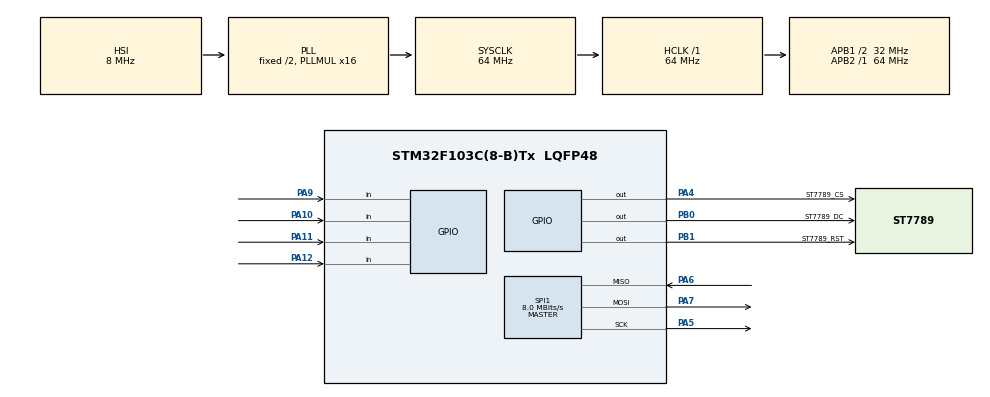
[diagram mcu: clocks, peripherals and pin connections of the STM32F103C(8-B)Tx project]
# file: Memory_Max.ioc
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Mcu.Family=STM32F1
Mcu.Name=STM32F103C(8-B)Tx
Mcu.Package=LQFP48
NVIC.PriorityGroup=NVIC_PRIORITYGROUP_4
PA10.GPIO_PuPd=GPIO_PULLUP
PA10.Signal=GPIO_Input
PA11.GPIO_PuPd=GPIO_PULLUP
PA11.Signal=GPIO_Input
PA12.GPIO_PuPd=GPIO_PULLUP
PA12.Signal=GPIO_Input
PA13.Mode=Serial_Wire
PA13.Signal=SYS_JTMS-SWDIO
PA14.Mode=Serial_Wire
PA14.Signal=SYS_JTCK-SWCLK
PA4.GPIO_Label=ST7789_CS 
PA4.Signal=GPIO_Output
PA5.Mode=Full_Duplex_Master
PA5.Signal=SPI1_SCK
PA6.Mode=Full_Duplex_Master
PA6.Signal=SPI1_MISO
PA7.Mode=Full_Duplex_Master
PA7.Signal=SPI1_MOSI
PA9.GPIO_PuPd=GPIO_PULLUP
PA9.Signal=GPIO_Input
PB0.GPIO_Label=ST7789_DC 
PB0.Signal=GPIO_Output
PB1.GPIO_Label=ST7789_RST 
PB1.Signal=GPIO_Output
ProjectManager.HeapSize=0x200
ProjectManager.StackSize=0x400
ProjectManager.TargetToolchain=STM32CubeIDE
RCC.AHBFreq_Value=64000000
RCC.APB1CLKDivider=RCC_HCLK_DIV2
RCC.APB1Freq_Value=32000000
RCC.APB1TimFreq_Value=64000000
RCC.APB2Freq_Value=64000000
RCC.APB2TimFreq_Value=64000000
RCC.HCLKFreq_Value=64000000
RCC.PLLMUL=RCC_PLL_MUL16
RCC.SYSCLKFreq_VALUE=64000000
RCC.SYSCLKSource=RCC_SYSCLKSOURCE_PLLCLK
RCC.USBFreq_Value=64000000
SPI1.BaudRatePrescaler=SPI_BAUDRATEPRESCALER_8
SPI1.CLKPolarity=SPI_POLARITY_HIGH
SPI1.CalculateBaudRate=8.0 MBits/s
SPI1.Direction=SPI_DIRECTION_2LINES
SPI1.Mode=SPI_MODE_MASTER
SPI1.VirtualType=VM_MASTER
board=custom

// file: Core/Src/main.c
/* USER CODE BEGIN Header */
/**
  ******************************************************************************
  * @file           : main.c
  * @brief          : Main program body
  ******************************************************************************
  * @attention
  *
  * <h2><center>&copy; Copyright (c) 2025 STMicroelectronics.
  * All rights reserved.</center></h2>
  *
  * This software component is licensed by ST under BSD 3-Clause license,
  * the "License"; You may not use this file except in compliance with the
  * License. You may obtain a copy of the License at:
  *                        opensource.org/licenses/BSD-3-Clause
  *
  ******************************************************************************
  */
/* USER CODE END Header */
#include "main.h"

/* USER CODE BEGIN Includes */
#include "st7789\st7789.h"
#include "stdbool.h"
#include "jogo.h"
#include "stdlib.h"
#include "stdio.h"
/* USER CODE END Includes */

SPI_HandleTypeDef hspi1;

/* USER CODE BEGIN PV */
static const uint64_t hearts[50] = {0x00,0x00,0x1E0003E000,0x60800C1800,0x9E6013E400,0x37F902FFA00,0x7FFE85FFD00,0xFFFFCBFFE80,0xBFFF57FFF40,0x17FFFBFFFFE0,0x3FFFFEFFFFA0,0x2FFFFDFFFFD0,0x5FFFFFFFFFF0,0x5FFFFFFFFFE8,0xBFFFFFFFFFE8,0xBFFFFFFFFFF4,0xBFFFFFFFFFF4,0xBFFFFFFFFFF4,0x17FFFFFFFFFF4,0x17FFFFFFFFFF4,0x17FFFFFFFFFF4,0xBFFFFFFFFFF4,0xBFFFFFFFFFF4,0xBFFFFFFFFFF4,0xBFFFFFFFFFE8,0x7FFFFFFFFFE8,0x5FFFFFFFFFE8,0x5FFFFFFFFFD0,0x2FFFFFFFFFD0,0x3FFFFFFFFFA0,0x17FFFFFFFFE0,0x1FFFFFFFFF40,0xBFFFFFFFFC0,0x5FFFFFFFE80,0x7FFFFFFFD00,0x2FFFFFFFA00,0x17FFFFFFE00,0xBFFFFFF400,0x5FFFFFE800,0x2FFFFFD000,0x17FFFFA000,0xBFFFE4000,0x5FFFD8000,0x27FFA0000,0x1BFE40000,0x4FD80000,0x37200000,0x8C00000,0x7000000,0x00};
static const uint64_t spades[50] = {0x13900000,0x6FEC0000,0x9FF20000,0x37FFD0000,0x4FFFE8000,0xBFFFF6000,0x17FFFFB000,0x2FFFFFF800,0x5FFFFFFC00,0xBFFFFFFE00,0x17FFFFFFB00,0x2FFFFFFFD00,0x7FFFFFFFE80,0x5FFFFFFFF40,0xBFFFFFFFFC0,0x1FFFFFFFFFA0,0x17FFFFFFFFF0,0x2FFFFFFFFFD0,0x2FFFFFFFFFE8,0x5FFFFFFFFFE8,0x5FFFFFFFFFF8,0xBFFFFFFFFFF4,0xBFFFFFFFFFF4,0xBFFFFFFFFFF4,0xBFFFFFFFFFFA,0xBFFFFFFFFFFA,0x17FFFFFFFFFFA,0x17FFFFFFFFFFA,0x17FFFFFFFFFFA,0x17FFFFFFFFFFA,0x7FFFFFFFFFFA,0xBFFFFFFFFFFA,0xBFFFFFFFFFF4,0xBFFFFFFFFFF4,0x7FFFFFFFFFF4,0x5FFFFFFFFFE8,0x3FFFFFFFFFF8,0x3FFFFFFFFFD0,0x17FFFFFFFFA0,0xBFFFFFFFF40,0x5FFEFDFFE80,0x27FDFE7FD00,0x18E7FF8E200,0x61DFEE1C00,0xE7FF5E000,0xFFF40000,0xBFF40000,0x17FFA0000,0x17FFF0000,0x7FFC0000};
static const uint64_t clubs[50] = {0xDFCC0000,0x13FF20000,0x2FFFD0000,0x5FFFF8000,0xFFFFE8000,0xBFFFF4000,0x17FFFFE000,0x17FFFFA000,0x2FFFFFA000,0x2FFFFFD000,0x2FFFFFD000,0x2FFFFFD000,0x2FFFFFD000,0x2FFFFFD000,0x7FFFFFF000,0x18FFFFFCC00,0x27FFFFFF300,0x5FFFFFFFC80,0xBFFFFFFFF40,0x17FFFFFFFFA0,0x2FFFFFFFFFF0,0x7FFFFFFFFFD0,0x5FFFFFFFFFE8,0xFFFFFFFFFFE8,0xBFFFFFFFFFF4,0xBFFFFFFFFFF4,0xBFFFFFFFFFF4,0x17FFFFFFFFFF4,0x17FFFFFFFFFF4,0x17FFFFFFFFFF4,0x3FFFFFFFFFF4,0xBFFFFFFFFFF4,0xBFFFFFFFFFF4,0xBFFFFFFFFFFC,0x5FFFFFFFFFE8,0x7FFFFFFFFFF8,0x2FFFFFFFFFD0,0x3FFFFFFFFFA0,0x1FFFFFFFFF40,0x9FFDFDFFE80,0x6FFBFE7FD00,0x1087FF84200,0xF7DFEF3C00,0x8BFF44000,0xBFFC0000,0xFFF40000,0x17FFA0000,0x3FFFE0000,0x2FFFC0000,0x00};
static const uint64_t diamonds[50] = {0xB400000,0x1FE00000,0x37F00000,0x2FD00000,0x5FE80000,0xBFF40000,0x17FFA0000,0x2FFFD0000,0x7FFFE8000,0xDFFFFC000,0xBFFFF6000,0x17FFFFA000,0x2FFFFFD000,0x5FFFFFE800,0xBFFFFFF400,0x1FFFFFFFA00,0x3FFFFFFFF00,0x2FFFFFFFD80,0x5FFFFFFFE80,0xBFFFFFFFF40,0x17FFFFFFFFA0,0x2FFFFFFFFFD0,0x5FFFFFFFFFE8,0xFFFFFFFFFFFC,0xBFFFFFFFFFF4,0xFFFFFFFFFFFC,0x5FFFFFFFFFE8,0x2FFFFFFFFFD0,0x17FFFFFFFFA0,0xBFFFFFFFF40,0x5FFFFFFFE80,0x2FFFFFFFD00,0x37FFFFFFF00,0x1FFFFFFFE00,0xBFFFFFF400,0x5FFFFFE800,0x2FFFFFD000,0x17FFFFA000,0xBFFFF4000,0xDFFFFC000,0x7FFFF8000,0x2FFFD0000,0x17FFA0000,0xBFF40000,0x5FE80000,0x2FD00000,0x17B00000,0x1FE00000,0xB400000,0x4800000};
static const uint16_t fundocarta[][(50*50/2)]  = {
  0x4eeb, 0x14f5, 0x51ec, 0x8eeb, 0x18f6, 0xd7f5, 0x39f6, 0xf8f5, 0x76ed, 0xb3f4, 0x96f5, 0x55ed, 0xf7f5, 0xf0eb, 0x59f6, 0x38f6, 0x8eeb, 0xd7f5, 0x59f6, 0x92ec, 0x14f5, 0x59f6, 0x55f5, 0x92f4, 0x18f6, 0x18f6, 0x92ec, 0x55f5, 0x59f6, 0x34f5, 0x92ec, 0x59f6, 0xd7f5, 0x8eeb, 0x38f6, 0x39f6, 0xd0eb, 0xf7f5, 0x55ed, 0x96f5, 0xb3f4, 0x76ed, 0x18f6, 0x39f6, 0xd7f5, 0x18f6, 0x6eeb, 0x51ec, 0x34f5, 0x4eeb,
  0x4deb, 0x31f4, 0x14f5, 0xf0eb, 0x34ed, 0x18f6, 0x59f6, 0x18f6, 0xb3ec, 0x92ec, 0x76f5, 0x14ed, 0x51ec, 0xb7f5, 0x35f5, 0x92f4, 0x18f6, 0xf4f4, 0xf4f4, 0x55f5, 0x55f5, 0x14f5, 0xd3ec, 0xb6f5, 0xb3f4, 0xb3f4, 0xb6f5, 0xd3ec, 0x14f5, 0x55f5, 0x55f5, 0xf4f4, 0xf4f4, 0x18f6, 0xb2f4, 0x35f5, 0xb7f5, 0x51ec, 0x14ed, 0x76f5, 0xb2ec, 0xb3ec, 0x18f6, 0x59f6, 0x18f6, 0x14ed, 0xd0eb, 0x14f5, 0x31f4, 0x4deb,
  0x4deb, 0x92f4, 0xf0eb, 0x6eeb, 0x55ed, 0x59f6, 0xb6ed, 0x79f6, 0xd3ec, 0x92ec, 0x55f5, 0x35ed, 0x96f5, 0x52ec, 0xf8f5, 0xb7f5, 0x31ec, 0x96f5, 0xf7f5, 0xb3f4, 0x35f5, 0xf7f5, 0x35f5, 0xf3f4, 0x96f5, 0xb6f5, 0xf3f4, 0x35f5, 0xf7f5, 0x35f5, 0xb3f4, 0xf7f5, 0x96f5, 0x31ec, 0xb7f5, 0xf8f5, 0x51ec, 0x96f5, 0x35ed, 0x55f5, 0x92ec, 0xd3ec, 0x79f6, 0xb6f5, 0x59f6, 0x55ed, 0x6eeb, 0xf0eb, 0x92f4, 0x4deb,
  0x4deb, 0xb3f4, 0xcfeb, 0x4eeb, 0x35ed, 0xf8f5, 0x9af6, 0xd7ed, 0xd3ec, 0x72ec, 0x55f5, 0x14ed, 0xdbf6, 0xafeb, 0x7af6, 0x9af6, 0x4eeb, 0x59f6, 0x79f6, 0xb3f4, 0xb6f5, 0x59f6, 0xb6f5, 0xf4f4, 0x39f6, 0x39f6, 0xf4f4, 0xb7f5, 0x59f6, 0xb7f5, 0xb3f4, 0x79f6, 0x59f6, 0x4deb, 0x9af6, 0x79f6, 0xafeb, 0xdbfe, 0x14ed, 0x55f5, 0x72ec, 0xd3ec, 0xd7ed, 0x9af6, 0xf8f5, 0x35ed, 0x4eeb, 0xcfeb, 0xb3f4, 0x4deb,
  0x4deb, 0x72f4, 0x92f4, 0xcfeb, 0x38f6, 0xf7f5, 0x59f6, 0x38f6, 0x76ed, 0xd3f4, 0xb6f5, 0x55ed, 0xcfeb, 0xf7f5, 0x55f5, 0xb3ec, 0x59f6, 0xb3ec, 0x55f5, 0x76f5, 0xf3ec, 0x96f5, 0xf4f4, 0x76f5, 0x34f5, 0x35f5, 0x76f5, 0xf4f4, 0xb6f5, 0xf3ec, 0x76f5, 0x55f5, 0xb3ec, 0x59f6, 0xb3ec, 0x55f5, 0xf7f5, 0xcfeb, 0x55ed, 0x96f5, 0xd3f4, 0x96ed, 0x38f6, 0x59f6, 0xf7f5, 0x38f6, 0xafeb, 0x92ec, 0x72f4, 0x4deb,
  0x4deb, 0x92f4, 0xf3f4, 0xcfeb, 0x35ed, 0x38f6, 0x59f6, 0x18f6, 0xd3ec, 0x92f4, 0x76f5, 0x14ed, 0x14f5, 0xd3ec, 0x96f5, 0x14f5, 0xf3ec, 0x55f5, 0x35f5, 0xd3ec, 0x55f5, 0x34f5, 0xd3f4, 0x35f5, 0xd3f4, 0xd3f4, 0x35f5, 0xb3ec, 0x34f5, 0x55f5, 0xd3ec, 0x35f5, 0x55f5, 0xd3ec, 0x14f5, 0x96f5, 0xd3ec, 0x14f5, 0x14ed, 0x76f5, 0xb2ec, 0xd3ec, 0x38f6, 0x59f6, 0x38f6, 0x35ed, 0xafeb, 0xf4f4, 0x92f4, 0x4deb,
  0x4deb, 0xb3f4, 0xcfeb, 0x6eeb, 0x75ed, 0x59f6, 0x96ed, 0x9af6, 0xf4ec, 0x72ec, 0x35f5, 0x34ed, 0x9af6, 0xf0eb, 0x79f6, 0x9af6, 0x8eeb, 0x38f6, 0x79f6, 0xd3f4, 0x96f5, 0x59f6, 0xb7f5, 0xf3f4, 0x59f6, 0x39f6, 0xf4f4, 0xb7f5, 0x59f6, 0x96f5, 0xd3f4, 0x79f6, 0x38f6, 0x8eeb, 0x7af6, 0x59f6, 0xf0eb, 0x9af6, 0x34ed, 0x35ed, 0x92ec, 0xf4ec, 0x9af6, 0x96ed, 0x59f6, 0x75ed, 0x4eeb, 0xcfeb, 0xb3f4, 0x4deb,
  0x4deb, 0x35f5, 0x10ec, 0x6eeb, 0x14ed, 0x18f6, 0xbaf6, 0xd7f5, 0xb3ec, 0x51ec, 0x34f5, 0x76ed, 0x10ec, 0x96f5, 0x96f5, 0x35f5, 0xd7f5, 0xd3ec, 0xf8f5, 0x76f5, 0xd3ec, 0x59f6, 0x75f5, 0x34f5, 0xd7f5, 0xd7f5, 0x34f5, 0x75f5, 0x59f6, 0xb3ec, 0x75f5, 0xf8f5, 0xd3ec, 0xd7f5, 0x34f5, 0x96f5, 0x96f5, 0x10ec, 0x76ed, 0x14f5, 0x51ec, 0xb3ec, 0xd7f5, 0xbaf6, 0x18f6, 0x14ed, 0x6eeb, 0x10ec, 0x35f5, 0x4deb,
  0x2deb, 0xf0eb, 0x76f5, 0x10ec, 0x38f6, 0xf8f5, 0x59f6, 0x39f6, 0x96ed, 0xd3f4, 0xb6f5, 0x72ec, 0x75f5, 0x14ed, 0x14f5, 0x92f4, 0x35ed, 0x76f5, 0x11ec, 0xf4ec, 0x18f6, 0xcfeb, 0x51ec, 0xf8f5, 0xcfeb, 0xcfeb, 0xf8f5, 0x51ec, 0xcfeb, 0xf8f5, 0xf4ec, 0x31ec, 0x76f5, 0x35ed, 0x92f4, 0x14f5, 0xf4ec, 0x76f5, 0x72ec, 0x96f5, 0xd3f4, 0x96ed, 0x39f6, 0x59f6, 0xf7f5, 0x39f6, 0xf0eb, 0x96f5, 0xf0eb, 0x2deb,
  0x4deb, 0x92f4, 0xf0eb, 0x8eeb, 0x55ed, 0x39f6, 0x59f6, 0x38f6, 0xf4ec, 0xb3f4, 0xb6f5, 0x75ed, 0x76f5, 0x10ec, 0x18f6, 0x18f6, 0xd0eb, 0x76f5, 0x79f6, 0xb3ec, 0xd3f4, 0x9af6, 0x76f5, 0x72ec, 0x59f6, 0x59f6, 0x72f4, 0x76f5, 0x9af6, 0xd3ec, 0xb3f4, 0x79f6, 0x76f5, 0xd0eb, 0x18f6, 0x18f6, 0x10ec, 0x75f5, 0x75ed, 0xb6f5, 0xb3f4, 0xf4ec, 0x38f6, 0x59f6, 0x39f6, 0x55ed, 0x8eeb, 0xf0eb, 0x92f4, 0x4deb,
  0x2deb, 0x72f4, 0xafeb, 0x4eeb, 0x75ed, 0x59f6, 0x96ed, 0x9af6, 0xf4ec, 0x72ec, 0x35f5, 0x55ed, 0x55f5, 0x35f5, 0xd7f5, 0xd7f5, 0x35f5, 0x96f5, 0x38f6, 0x96f5, 0x55f5, 0x79f6, 0xf7f5, 0x75f5, 0x59f6, 0x39f6, 0x55f5, 0xf7f5, 0x79f6, 0x55f5, 0x76f5, 0x38f6, 0x96f5, 0x35f5, 0xd7f5, 0xd7f5, 0x35f5, 0x55f5, 0x35ed, 0x35f5, 0x72ec, 0xf4ec, 0x9af6, 0x96ed, 0x79f6, 0x75ed, 0x4deb, 0xafeb, 0x92f4, 0x2deb,
  0x4deb, 0x51f4, 0x10ec, 0xafeb, 0xf4ec, 0x18f6, 0xbaf6, 0xd7f5, 0x92ec, 0x10ec, 0xd3f4, 0x72ec, 0x35f5, 0xf3ec, 0xf4f4, 0x92f4, 0x14ed, 0x55f5, 0x31ec, 0xf3ec, 0xd7f5, 0xf0eb, 0x72ec, 0xd7f5, 0xf0eb, 0xf0eb, 0xd7f5, 0x72ec, 0xf0eb, 0xd7f5, 0xf3ec, 0x31ec, 0x55f5, 0x14ed, 0x92f4, 0xf4f4, 0xf4ec, 0x55f5, 0x72ec, 0xb3ec, 0x31ec, 0x92ec, 0xd7f5, 0xbaf6, 0x18f6, 0xf4ec, 0xafeb, 0x10ec, 0x51f4, 0x4deb,
  0x2deb, 0xcfeb, 0x55f5, 0x10ec, 0x39f6, 0xf8f5, 0x59f6, 0x39f6, 0x96ed, 0xd3f4, 0xb6f5, 0xd7f5, 0x6eeb, 0x92f4, 0xb6f5, 0x55f5, 0xb3f4, 0x51ec, 0x9af6, 0x92f4, 0x8eeb, 0xfcf6, 0x35f5, 0xcfeb, 0x59f6, 0x59f6, 0xcfeb, 0x34f5, 0xfcf6, 0x8eeb, 0x92f4, 0x7af6, 0x51ec, 0xb2f4, 0x35f5, 0xb7f5, 0xb2f4, 0x8eeb, 0xd7ed, 0x96f5, 0xd3f4, 0x96ed, 0x59f6, 0x59f6, 0xf8f5, 0x39f6, 0xf0eb, 0x55f5, 0xcfeb, 0x2deb,
  0x4deb, 0x55f5, 0xf0eb, 0x4eeb, 0x96ed, 0x38f6, 0x59f6, 0x38f6, 0x14ed, 0xb3f4, 0xb6f5, 0xf3ec, 0xdbfe, 0x14f5, 0x38f6, 0x79f6, 0xf3f4, 0x7af6, 0x38f6, 0xd7f5, 0x79f6, 0x38f6, 0x59f6, 0x18f6, 0x79f6, 0x79f6, 0x18f6, 0x59f6, 0x38f6, 0x59f6, 0xd7f5, 0x38f6, 0x7af6, 0xf3f4, 0x79f6, 0x18f6, 0x14f5, 0xdbfe, 0xf4ec, 0xb6f5, 0xb3f4, 0x14ed, 0x38f6, 0x59f6, 0x38f6, 0x96ed, 0x4deb, 0xf0eb, 0x55f5, 0x4deb,
  0x4deb, 0xd3f4, 0xcfeb, 0x6eeb, 0x55ed, 0x59f6, 0x96ed, 0x9af6, 0xd3ec, 0x92ec, 0x76f5, 0xf4ec, 0x92ec, 0xd3ec, 0x55f5, 0xd3f4, 0xf4ec, 0xf4f4, 0x14f5, 0xd3ec, 0xf4ec, 0x34f5, 0xb3f4, 0x14f5, 0xd3f4, 0xd3f4, 0x14f5, 0xb3f4, 0x34f5, 0xf4f4, 0xd3ec, 0x14f5, 0xf4f4, 0xf4ec, 0xd3f4, 0x35f5, 0xd3ec, 0x92ec, 0xf4ec, 0x75f5, 0x92f4, 0xd3ec, 0x9af6, 0x96ed, 0x59f6, 0x55ed, 0x6eeb, 0xcfeb, 0xd3f4, 0x4deb,
  0x4deb, 0x92f4, 0x55f5, 0xcfeb, 0xf4ec, 0x18f6, 0x9af6, 0xf7f5, 0x92ec, 0x51ec, 0x14f5, 0x35ed, 0xf0eb, 0x35f5, 0x55f5, 0xd3f4, 0x75f5, 0xb3ec, 0x96f5, 0xf4f4, 0x92ec, 0xd7f5, 0xf4f4, 0xf3ec, 0x55f5, 0x55f5, 0xf3ec, 0xf4f4, 0xd7f5, 0x92ec, 0xf4f4, 0x96f5, 0xb3ec, 0x75f5, 0xd3f4, 0x55f5, 0x35ed, 0x10ec, 0x35ed, 0x14f5, 0x51ec, 0x92ec, 0xd7f5, 0x9af6, 0x18f6, 0xf4ec, 0xcfeb, 0x55f5, 0x92f4, 0x4deb,
  0x4eeb, 0xd3f4, 0x51ec, 0xafeb, 0x18f6, 0xf7f5, 0x59f6, 0x18f6, 0x76ed, 0xb3f4, 0x76f5, 0xd3ec, 0x9eff, 0xd3f4, 0x59f6, 0xbbf6, 0x72ec, 0xfbf6, 0x38f6, 0xb7f5, 0xdbfe, 0x18f6, 0x79f6, 0x38f6, 0x59f6, 0x59f6, 0x38f6, 0x79f6, 0x18f6, 0xdbf6, 0xb7f5, 0x38f6, 0xfbf6, 0x72ec, 0xbbf6, 0x59f6, 0xd3f4, 0x9eff, 0xd3ec, 0x75f5, 0xb3f4, 0x76ed, 0x18f6, 0x39f6, 0xf7f5, 0x18f6, 0xafeb, 0x51ec, 0xd3f4, 0x6eeb,
  0x2deb, 0x92f4, 0xafeb, 0x4eeb, 0x96ed, 0x18f6, 0x59f6, 0x18f6, 0x35ed, 0x92f4, 0x76f5, 0x75ed, 0x92ec, 0x51ec, 0xb7f5, 0x76f5, 0x31ec, 0xf4f4, 0x18f6, 0x72ec, 0x52ec, 0x39f6, 0x14f5, 0x51ec, 0xb7f5, 0xb7f5, 0x51ec, 0xf4f4, 0x39f6, 0x72ec, 0x92ec, 0x18f6, 0xf4f4, 0x31ec, 0x76f5, 0xb7f5, 0x51ec, 0x92ec, 0x55ed, 0x75f5, 0x92f4, 0x35ed, 0x18f6, 0x59f6, 0x18f6, 0x96ed, 0x4eeb, 0xafeb, 0x92f4, 0x2deb,
  0x4deb, 0x92f4, 0xf0eb, 0x8eeb, 0x55ed, 0x59f6, 0xd7f5, 0x79f6, 0xd3ec, 0xb3f4, 0x96f5, 0xf4ec, 0x92ec, 0x55f5, 0x35f5, 0xb3f4, 0xb6f5, 0x14f5, 0xd3f4, 0x14f5, 0x55f5, 0xd3f4, 0xb3ec, 0x96f5, 0x92f4, 0x92f4, 0x96f5, 0xb3ec, 0xd3f4, 0x55f5, 0x34ed, 0xd3f4, 0x14f5, 0xb6f5, 0xb3f4, 0x34f5, 0x55f5, 0x92ec, 0xf4ec, 0x96f5, 0xb3f4, 0xd3ec, 0x79f6, 0xd7f5, 0x59f6, 0x55ed, 0x6eeb, 0xf0eb, 0x92f4, 0x4deb,
  0x4deb, 0xf0eb, 0xf4f4, 0xf0eb, 0xf4ec, 0x18f6, 0x59f6, 0xf8f5, 0x92ec, 0x72ec, 0x55f5, 0x14ed, 0x18f6, 0xb3f4, 0x18f6, 0x38f6, 0x92ec, 0x18f6, 0x38f6, 0x55f5, 0xb7f5, 0x38f6, 0xd7f5, 0x75f5, 0x38f6, 0x18f6, 0x76f5, 0xd7f5, 0x38f6, 0xb7f5, 0x55f5, 0x38f6, 0x18f6, 0x92ec, 0x18f6, 0x18f6, 0xb3f4, 0x18f6, 0x14ed, 0x55f5, 0x92f4, 0x92ec, 0xf8f5, 0x59f6, 0x18f6, 0xf4ec, 0xf0eb, 0xf4f4, 0xf0eb, 0x4deb,
  0x4deb, 0x35f5, 0x31ec, 0x6eeb, 0xf8f5, 0xf7f5, 0x39f6, 0xf8f5, 0x75ed, 0x92ec, 0x75f5, 0x75ed, 0x96f5, 0xafeb, 0x59f6, 0x18f6, 0x4eeb, 0x76f5, 0x9af6, 0x51ec, 0xb2ec, 0xbaf6, 0x55f5, 0x31ec, 0x39f6, 0x39f6, 0x31ec, 0x55f5, 0xbaf6, 0x92ec, 0x51ec, 0x9af6, 0x96f5, 0x4eeb, 0x38f6, 0x39f6, 0xafeb, 0x96f5, 0x75ed, 0x55f5, 0xb2ec, 0x75ed, 0x18f6, 0x39f6, 0xd7f5, 0xf8f5, 0x6eeb, 0x31ec, 0x35f5, 0x4deb,
  0x2deb, 0x51f4, 0xafeb, 0x6eeb, 0xb7f5, 0xf8f5, 0x39f6, 0xf8f5, 0x35ed, 0x92f4, 0x76f5, 0xf3ec, 0xb3ec, 0x76ed, 0x34f5, 0x92f4, 0xd7f5, 0x34f5, 0xb2f4, 0x35f5, 0x96f5, 0x92f4, 0xb2ec, 0xd7f5, 0x51f4, 0x71f4, 0xd7f5, 0xb3ec, 0x92f4, 0x96f5, 0x35f5, 0xb3f4, 0x34f5, 0xd7f5, 0x92f4, 0x34f5, 0x76f5, 0xb3ec, 0xd3ec, 0x75f5, 0xb2ec, 0x55ed, 0xf8f5, 0x39f6, 0xf8f5, 0xb7f5, 0x6eeb, 0x8feb, 0x51f4, 0x2deb,
  0x4deb, 0xd3f4, 0x92f4, 0xafeb, 0x35ed, 0x38f6, 0xf7f5, 0x39f6, 0xb3ec, 0x92ec, 0x76f5, 0x55ed, 0x14f5, 0x14f5, 0xd7f5, 0x76f5, 0x14f5, 0x55f5, 0xd7f5, 0x34f5, 0x35f5, 0xf7f5, 0x55f5, 0x35f5, 0xb6f5, 0xb6f5, 0x35f5, 0x55f5, 0xf8f5, 0x35f5, 0x34f5, 0xd7f5, 0x55f5, 0x14f5, 0x76f5, 0xd7f5, 0x14f5, 0x14f5, 0x35ed, 0x75f5, 0x92ec, 0xb3ec, 0x39f6, 0xf8f5, 0x38f6, 0x34ed, 0x8feb, 0x92f4, 0xd3f4, 0x4deb,
  0x4deb, 0x72f4, 0xb3f4, 0xcfeb, 0x14ed, 0x18f6, 0x38f6, 0x18f6, 0x92ec, 0x72ec, 0x55f5, 0x35ed, 0x9af6, 0xafeb, 0x79f6, 0x7af6, 0x2deb, 0x18f6, 0x79f6, 0x92ec, 0x55f5, 0x79f6, 0x96f5, 0xb3f4, 0x39f6, 0x39f6, 0xb2f4, 0x96f5, 0x79f6, 0x55f5, 0x92f4, 0x79f6, 0x38f6, 0x2deb, 0x7af6, 0x79f6, 0xafeb, 0x7af6, 0x35ed, 0x55f5, 0x92f4, 0xb2ec, 0x18f6, 0x38f6, 0x38f6, 0x14ed, 0xcfeb, 0xd3f4, 0x72f4, 0x4deb,
  0x4deb, 0xb2f4, 0xcfeb, 0x6eeb, 0xd7f5, 0xf7f5, 0x39f6, 0xf8f5, 0x55ed, 0x92f4, 0x76f5, 0x34ed, 0x92ec, 0x76f5, 0x75f5, 0xd3f4, 0xb7f5, 0x14f5, 0x35f5, 0x35f5, 0x35f5, 0x35f5, 0xf3f4, 0x96f5, 0xf4f4, 0xf4f4, 0x96f5, 0xf3ec, 0x55f5, 0x35f5, 0x35f5, 0x35f5, 0x14f5, 0xb7f5, 0xd3f4, 0x55f5, 0x76f5, 0x92ec, 0x34ed, 0x76f5, 0xb3f4, 0x55ed, 0xf8f5, 0x39f6, 0xf7f5, 0xd7f5, 0x6eeb, 0xcfeb, 0xb3f4, 0x4deb,
  0x4deb, 0x92f4, 0xcfeb, 0x6eeb, 0xd7f5, 0xf7f5, 0x39f6, 0xf8f5, 0x55ed, 0x92ec, 0x76f5, 0x14ed, 0x92ec, 0x76f5, 0x55f5, 0xd3f4, 0xb7f5, 0x14f5, 0x34f5, 0x35f5, 0x35f5, 0x35f5, 0xf3f4, 0x96f5, 0xf3f4, 0xf3f4, 0x96f5, 0xd3f4, 0x35f5, 0x35f5, 0x35f5, 0x35f5, 0x14f5, 0xb7f5, 0xd3f4, 0x55f5, 0x76f5, 0x92ec, 0x14ed, 0x76f5, 0xb3f4, 0x55ed, 0xf8f5, 0x39f6, 0xf7f5, 0xd7f5, 0x6eeb, 0xcfeb, 0xb2f4, 0x4deb,
  0x4deb, 0x72f4, 0xb3f4, 0xcfeb, 0x14ed, 0x18f6, 0x38f6, 0x18f6, 0x92ec, 0x92ec, 0x55f5, 0x35ed, 0x7af6, 0xafeb, 0x79f6, 0x7af6, 0x4deb, 0x18f6, 0x79f6, 0x92ec, 0x55f5, 0x79f6, 0x96f5, 0xb3f4, 0x39f6, 0x39f6, 0xb3f4, 0x96f5, 0x79f6, 0x55f5, 0x92ec, 0x79f6, 0x18f6, 0x2deb, 0x7af6, 0x79f6, 0xafeb, 0x7af6, 0x35ed, 0x55f5, 0x92ec, 0x92ec, 0x18f6, 0x38f6, 0x18f6, 0x14ed, 0xcfeb, 0xd3f4, 0x72f4, 0x4deb,
  0x4deb, 0xd3f4, 0x92f4, 0xafeb, 0x34ed, 0x38f6, 0xf7f5, 0x59f6, 0xb3ec, 0x92ec, 0x55f5, 0x55ed, 0x14f5, 0x14f5, 0xd7f5, 0x76f5, 0x14f5, 0x55f5, 0xd7f5, 0x34f5, 0x35f5, 0xf8f5, 0x55f5, 0x35f5, 0xb6f5, 0xb7f5, 0x35f5, 0x55f5, 0xf8f5, 0x35f5, 0x34f5, 0xd7f5, 0x55f5, 0x14f5, 0x76f5, 0xd7f5, 0x14f5, 0x14f5, 0x55ed, 0x55f5, 0x92f4, 0xb3ec, 0x39f6, 0xf8f5, 0x38f6, 0x35ed, 0x8feb, 0xb2f4, 0xd3f4, 0x4deb,
  0x2deb, 0x51f4, 0x8feb, 0x6eeb, 0xb7f5, 0xf8f5, 0x39f6, 0xf8f5, 0x55ed, 0x92ec, 0x76f5, 0xd3ec, 0xb3ec, 0x76f5, 0x34f5, 0x92f4, 0xb7f5, 0x34f5, 0x92f4, 0x35f5, 0x96f5, 0x92ec, 0xb2ec, 0xd7f5, 0x51ec, 0x51f4, 0xd7f5, 0xb3ec, 0x92f4, 0x96f5, 0x35ed, 0xb2f4, 0x34f5, 0xd7f5, 0x92f4, 0x34f5, 0x76f5, 0xb3ec, 0xd3ec, 0x75f5, 0xb2f4, 0x55ed, 0xf8f5, 0x39f6, 0xf8f5, 0xb7f5, 0x6eeb, 0x8feb, 0x51f4, 0x2deb,
  0x4deb, 0x35f5, 0x31ec, 0x6eeb, 0xf8f5, 0xf7f5, 0x39f6, 0xf8f5, 0x75ed, 0x92ec, 0x75f5, 0x76ed, 0x96f5, 0xafeb, 0x39f6, 0x18f6, 0x6eeb, 0x76f5, 0x9af6, 0x51ec, 0xb2ec, 0xbaf6, 0x55f5, 0x31ec, 0x38f6, 0x39f6, 0x31ec, 0x55f5, 0xbaf6, 0x92ec, 0x51ec, 0x9af6, 0x96f5, 0x6eeb, 0x18f6, 0x39f6, 0xafeb, 0x76f5, 0x76ed, 0x55f5, 0x92ec, 0x75ed, 0x18f6, 0x39f6, 0xd7f5, 0xf8f5, 0x6eeb, 0x31ec, 0x35f5, 0x4deb,
  0x4deb, 0xf0eb, 0xf4f4, 0xf0eb, 0x14ed, 0x18f6, 0x59f6, 0x18f6, 0x92ec, 0x92ec, 0x75f5, 0x14ed, 0x38f6, 0xb3f4, 0x18f6, 0x38f6, 0x92ec, 0x18f6, 0x38f6, 0x55f5, 0xb7f5, 0x38f6, 0xd7f5, 0x76f5, 0x18f6, 0x18f6, 0x75f5, 0xd7f5, 0x38f6, 0xd7f5, 0x55f5, 0x38f6, 0x18f6, 0x92ec, 0x38f6, 0x18f6, 0xb3f4, 0x38f6, 0x14ed, 0x55f5, 0x92f4, 0x92ec, 0xf8f5, 0x59f6, 0x18f6, 0xf4ec, 0xf0eb, 0xf4f4, 0xf0eb, 0x4deb,
  0x4deb, 0x92f4, 0x10ec, 0x8eeb, 0x55ed, 0x59f6, 0xd7ed, 0x79f6, 0xd3ec, 0xb3f4, 0x96f5, 0xf3ec, 0x92ec, 0x55f5, 0x34f5, 0xb3f4, 0x96f5, 0x14f5, 0xd3f4, 0x14ed, 0x55f5, 0xd3f4, 0xb3f4, 0x96f5, 0x92f4, 0x92f4, 0x96f5, 0xb3f4, 0xd3f4, 0x55f5, 0x34f5, 0xd3f4, 0x14f5, 0x96f5, 0xb3f4, 0x34f5, 0x55f5, 0x92ec, 0xf3ec, 0x96f5, 0xb3f4, 0xd3ec, 0x79f6, 0xd7f5, 0x59f6, 0x55ed, 0x6eeb, 0xf0eb, 0x92f4, 0x4deb,
  0x2deb, 0x92f4, 0xafeb, 0x6eeb, 0x96ed, 0x18f6, 0x59f6, 0x18f6, 0x35ed, 0x92ec, 0x75f5, 0x75ed, 0x92ec, 0x51ec, 0xb7f5, 0x76f5, 0x51ec, 0xf4f4, 0x18f6, 0x92ec, 0x71ec, 0x39f6, 0x14f5, 0x51ec, 0xb7f5, 0xb7f5, 0x51ec, 0x14f5, 0x39f6, 0x72ec, 0x92ec, 0x18f6, 0xf4f4, 0x51ec, 0x75f5, 0xb7f5, 0x51ec, 0x92ec, 0x75ed, 0x75f5, 0x92f4, 0x35ed, 0x18f6, 0x59f6, 0x18f6, 0x96ed, 0x4eeb, 0xafeb, 0x92f4, 0x2deb,
  0x6eeb, 0xd3f4, 0x51ec, 0xafeb, 0x38f6, 0xf7f5, 0x59f6, 0x18f6, 0x76ed, 0xb2ec, 0x76f5, 0xd3ec, 0x9eff, 0xd3f4, 0x59f6, 0xbbf6, 0x72ec, 0xfbf6, 0x39f6, 0xb7f5, 0xdbf6, 0xf8f5, 0x79f6, 0x38f6, 0x59f6, 0x59f6, 0x38f6, 0x79f6, 0x18f6, 0xdbfe, 0xb7f5, 0x39f6, 0xfbf6, 0x72ec, 0xdbf6, 0x59f6, 0xd3ec, 0x9eff, 0xd3ec, 0x75f5, 0xb3f4, 0x76ed, 0x18f6, 0x39f6, 0xf7f5, 0x18f6, 0xafeb, 0x51ec, 0xd3f4, 0x6eeb,
  0x4deb, 0x92f4, 0x55f5, 0xcfeb, 0xf4ec, 0x18f6, 0x9af6, 0xf7f5, 0x92ec, 0x72ec, 0x35f5, 0x35ed, 0x10ec, 0x34f5, 0x55f5, 0xd3f4, 0x55f5, 0xb3ec, 0x96f5, 0xf4f4, 0x92ec, 0xb7f5, 0xf4f4, 0xd3ec, 0x55f5, 0x55f5, 0xd3ec, 0xf4f4, 0xd7f5, 0x92ec, 0xf4f4, 0x96f5, 0xb3ec, 0x55f5, 0xf3f4, 0x55f5, 0x34ed, 0x10ec, 0x35ed, 0x35f5, 0x72ec, 0x92ec, 0xf7f5, 0x9af6, 0x18f6, 0xf4ec, 0xcfeb, 0x55f5, 0x92f4, 0x4deb,
  0x4deb, 0xd3f4, 0xcfeb, 0x6eeb, 0x55ed, 0x59f6, 0x96ed, 0x9af6, 0xd3ec, 0xb2f4, 0x96f5, 0xf4ec, 0x92ec, 0xd3ec, 0x55f5, 0xd3f4, 0xf4ec, 0xf4f4, 0x14f5, 0xd3ec, 0xf4f4, 0x34f5, 0xb3ec, 0x14f5, 0xd3f4, 0xd3f4, 0x14f5, 0xb3f4, 0x34f5, 0xf4f4, 0xd3ec, 0x14f5, 0xf4f4, 0xf4ec, 0xd3f4, 0x35f5, 0xd3ec, 0x92ec, 0xf4ec, 0x96f5, 0xb3f4, 0xf3ec, 0x9af6, 0xb6ed, 0x59f6, 0x55ed, 0x6eeb, 0xcfeb, 0xd3f4, 0x4deb,
  0x4deb, 0x55f5, 0xf0eb, 0x4eeb, 0x76ed, 0x39f6, 0x59f6, 0x38f6, 0x14ed, 0xb3f4, 0x96f5, 0xf4ec, 0xdbfe, 0x14f5, 0x18f6, 0x79f6, 0xf3f4, 0x7af6, 0x38f6, 0xd7f5, 0x79f6, 0x38f6, 0x59f6, 0x18f6, 0x79f6, 0x79f6, 0x18f6, 0x59f6, 0x38f6, 0x79f6, 0xd7f5, 0x38f6, 0x7af6, 0xd3ec, 0x79f6, 0x38f6, 0x14f5, 0xdbf6, 0xf3ec, 0x96f5, 0xb3f4, 0x14ed, 0x38f6, 0x59f6, 0x38f6, 0x96ed, 0x4eeb, 0xf0eb, 0x35f5, 0x4deb,
  0x2deb, 0xafeb, 0x55f5, 0x10ec, 0x39f6, 0xf8f5, 0x59f6, 0x59f6, 0x96ed, 0xd3f4, 0x96f5, 0xd7f5, 0x8eeb, 0x92f4, 0xb7f5, 0x55f5, 0x92f4, 0x51ec, 0x9af6, 0x92ec, 0x8eeb, 0xfbf6, 0x35f5, 0xafeb, 0x59f6, 0x59f6, 0xcfeb, 0x34f5, 0x1cf7, 0x8eeb, 0x92ec, 0x7af6, 0x51ec, 0x92f4, 0x55f5, 0xb7f5, 0x92f4, 0x8eeb, 0xd7f5, 0x96f5, 0xd3f4, 0x96ed, 0x59f6, 0x59f6, 0xf8f5, 0x39f6, 0xf0eb, 0x55f5, 0xafeb, 0x2deb,
  0x4deb, 0x51f4, 0x10ec, 0xafeb, 0xf4ec, 0x18f6, 0xbaf6, 0xd7f5, 0x92ec, 0x11ec, 0xd3ec, 0x72ec, 0x35f5, 0xf4ec, 0xf4f4, 0x92f4, 0x14ed, 0x55f5, 0x31ec, 0xf3ec, 0xd7f5, 0xf0eb, 0x72ec, 0xd7f5, 0xf0eb, 0xf0eb, 0xd7f5, 0x72ec, 0xf0eb, 0xd7f5, 0xf3ec, 0x31ec, 0x55f5, 0x14ed, 0x92f4, 0xf4f4, 0xf4ec, 0x35f5, 0x72ec, 0xd3ec, 0x31ec, 0x92ec, 0xd7f5, 0xbaf6, 0x18f6, 0xf4ec, 0xafeb, 0x10ec, 0x51ec, 0x4deb,
  0x2deb, 0x92f4, 0xafeb, 0x4eeb, 0x75ed, 0x79f6, 0x96ed, 0x9af6, 0xf4ec, 0x72ec, 0x55f5, 0x35ed, 0x55f5, 0x35f5, 0xd7f5, 0xd7f5, 0x35f5, 0x96f5, 0x38f6, 0x96f5, 0x55f5, 0x79f6, 0xf7f5, 0x75f5, 0x59f6, 0x59f6, 0x55f5, 0xd7f5, 0x79f6, 0x55f5, 0x96f5, 0x38f6, 0x96f5, 0x35f5, 0xd7f5, 0xf7f5, 0x35f5, 0x55f5, 0x55ed, 0x55f5, 0x92ec, 0xf4ec, 0x9af6, 0x96ed, 0x79f6, 0x76ed, 0x4deb, 0xafeb, 0x72f4, 0x2deb,
  0x4deb, 0x92f4, 0xf0eb, 0x8eeb, 0x55ed, 0x39f6, 0x59f6, 0x38f6, 0xf4ec, 0xb3f4, 0xb7f5, 0x75ed, 0x76f5, 0x10ec, 0x38f6, 0x18f6, 0xcfeb, 0x76f5, 0x79f6, 0xb2f4, 0xd3f4, 0x9af6, 0x76f5, 0x72ec, 0x59f6, 0x59f6, 0x72ec, 0x76f5, 0x9af6, 0xd3f4, 0xb2f4, 0x79f6, 0x96f5, 0xcfeb, 0x18f6, 0x38f6, 0x10ec, 0x76f5, 0x75ed, 0xb6f5, 0xb3f4, 0xf4ec, 0x38f6, 0x59f6, 0x39f6, 0x75ed, 0x8eeb, 0xf0eb, 0x92f4, 0x4deb,
  0x2deb, 0xf0eb, 0x96f5, 0x10ec, 0x38f6, 0xf8f5, 0x59f6, 0x39f6, 0x96ed, 0xd3f4, 0xb6f5, 0x72ec, 0x55f5, 0x14ed, 0x14f5, 0x92f4, 0x35ed, 0x76f5, 0x31ec, 0xf4ec, 0x18f6, 0xcfeb, 0x51ec, 0xf8f5, 0xcfeb, 0xcfeb, 0xf8f5, 0x51ec, 0xd0eb, 0xf8f5, 0xf4ec, 0x31ec, 0x76f5, 0x35ed, 0x92f4, 0x14f5, 0x14ed, 0x75f5, 0x72ec, 0x96f5, 0xd3f4, 0x96ed, 0x39f6, 0x59f6, 0xf8f5, 0x39f6, 0xf0eb, 0x96f5, 0xf0eb, 0x2deb,
  0x4deb, 0x35f5, 0x10ec, 0x6eeb, 0x14ed, 0x18f6, 0xbaf6, 0xd7f5, 0xb3ec, 0x51ec, 0x14f5, 0x76ed, 0x11ec, 0x96f5, 0x96f5, 0x34f5, 0xd7f5, 0xd3ec, 0xf7f5, 0x76f5, 0xd3ec, 0x59f6, 0x76f5, 0x35f5, 0xd7f5, 0xd7f5, 0x35f5, 0x75f5, 0x59f6, 0xb3ec, 0x75f5, 0xf7f5, 0xd3ec, 0xd7f5, 0x34f5, 0x96f5, 0x96f5, 0x30ec, 0x75ed, 0x14f5, 0x51ec, 0xb3ec, 0xd7ed, 0xbaf6, 0x18f6, 0x14ed, 0x6eeb, 0x10ec, 0x35f5, 0x4deb,
  0x4deb, 0xb3f4, 0xcfeb, 0x6eeb, 0x75ed, 0x59f6, 0x96ed, 0x9af6, 0xf4ec, 0x72ec, 0x35f5, 0x34ed, 0x9af6, 0xd0eb, 0x79f6, 0x9af6, 0x8eeb, 0x38f6, 0x79f6, 0xb3f4, 0x96f5, 0x59f6, 0xb7f5, 0xf3f4, 0x39f6, 0x39f6, 0xf3f4, 0xb7f5, 0x59f6, 0x96f5, 0xb3f4, 0x79f6, 0x38f6, 0x6eeb, 0x7af6, 0x79f6, 0xf0eb, 0x9af6, 0x34ed, 0x35f5, 0x72f4, 0xf4ec, 0x9af6, 0x96ed, 0x59f6, 0x75ed, 0x4eeb, 0xcfeb, 0xb3f4, 0x4deb,
  0x4deb, 0x92f4, 0xf3f4, 0xcfeb, 0x35ed, 0x38f6, 0x59f6, 0x38f6, 0xd3ec, 0x92f4, 0x96f5, 0x14ed, 0x14f5, 0xd3ec, 0x96f5, 0x14f5, 0xf3ec, 0x55f5, 0x35f5, 0xd3ec, 0x55f5, 0x34f5, 0xd3ec, 0x35f5, 0xd3f4, 0xf3f4, 0x35f5, 0xd3ec, 0x35f5, 0x55f5, 0xd3ec, 0x35f5, 0x55f5, 0xd3ec, 0x14f5, 0x96f5, 0xd3ec, 0x14f5, 0x14ed, 0x76f5, 0xb3f4, 0xd3ec, 0x38f6, 0x59f6, 0x38f6, 0x35ed, 0xafeb, 0xf4f4, 0x92f4, 0x4deb,
  0x4deb, 0x72f4, 0x92ec, 0xcfeb, 0x38f6, 0xf7f5, 0x59f6, 0x38f6, 0x76ed, 0xd3f4, 0xb6f5, 0x55ed, 0xcfeb, 0xf7f5, 0x55f5, 0xb3ec, 0x59f6, 0xd3ec, 0x55f5, 0x76f5, 0xf4ec, 0x96f5, 0xf4f4, 0x76f5, 0x34f5, 0x34f5, 0x76f5, 0xf4f4, 0x96f5, 0xf4ec, 0x76f5, 0x55f5, 0xb3f4, 0x59f6, 0xb3ec, 0x55f5, 0xf7f5, 0xcfeb, 0x55ed, 0x96f5, 0xd3f4, 0x96ed, 0x38f6, 0x59f6, 0xf7f5, 0x38f6, 0xcfeb, 0x92f4, 0x72f4, 0x4deb,
  0x4deb, 0xb3f4, 0xcfeb, 0x4eeb, 0x35ed, 0xf8f5, 0x9af6, 0xd7ed, 0xd3ec, 0x72ec, 0x55f5, 0x14ed, 0xdbf6, 0xafeb, 0x7af6, 0x9af6, 0x4eeb, 0x59f6, 0x79f6, 0xb3f4, 0xb6f5, 0x59f6, 0xb6f5, 0xf3f4, 0x39f6, 0x39f6, 0xf4f4, 0xb6f5, 0x59f6, 0xb6f5, 0xb3f4, 0x79f6, 0x59f6, 0x4deb, 0x9af6, 0x7af6, 0xafeb, 0xdbf6, 0x14ed, 0x35f5, 0x72ec, 0xd3ec, 0xd7ed, 0x9af6, 0xf8f5, 0x35ed, 0x4eeb, 0xcfeb, 0xb3f4, 0x4deb,
  0x4deb, 0x92f4, 0xf0eb, 0x6eeb, 0x55ed, 0x59f6, 0xb6ed, 0x79f6, 0xd3ec, 0x92f4, 0x55f5, 0x35ed, 0x96f5, 0x72ec, 0xf8f5, 0xd7f5, 0x51ec, 0x96f5, 0xf7f5, 0xb3f4, 0x35f5, 0xf7f5, 0x35f5, 0xf3f4, 0xb6f5, 0xb6f5, 0xf3f4, 0x35f5, 0xf7f5, 0x35f5, 0xb3f4, 0xf7f5, 0x96f5, 0x31ec, 0xd7f5, 0xf8f5, 0x71ec, 0x96f5, 0x35ed, 0x55f5, 0x92f4, 0xd3ec, 0x7af6, 0xb6ed, 0x59f6, 0x55ed, 0x6eeb, 0xd0eb, 0x92f4, 0x4deb,
  0x4deb, 0x31f4, 0x14f5, 0xf0eb, 0x34ed, 0x18f6, 0x59f6, 0x18f6, 0xb3ec, 0x92f4, 0x76f5, 0x14ed, 0x51ec, 0xb7f5, 0x35f5, 0x92f4, 0x18f6, 0xf4f4, 0xf4f4, 0x55f5, 0x55f5, 0x14f5, 0xd3ec, 0xb6f5, 0xb3ec, 0xb3f4, 0xb7f5, 0xd3ec, 0x14f5, 0x55f5, 0x55f5, 0xf4f4, 0xf4f4, 0x18f6, 0x92ec, 0x35f5, 0xb7f5, 0x51ec, 0x14ed, 0x76f5, 0xb3f4, 0xb3ec, 0x18f6, 0x59f6, 0x18f6, 0x34ed, 0xd0eb, 0x14f5, 0x31f4, 0x4deb,
  0x4eeb, 0x14f5, 0x31ec, 0x8eeb, 0x18f6, 0xf7f5, 0x59f6, 0x18f6, 0x76ed, 0xb3f4, 0x96f5, 0x55ed, 0xf7f5, 0xf0eb, 0x39f6, 0x38f6, 0x8eeb, 0xd7f5, 0x59f6, 0x92ec, 0x14f5, 0x59f6, 0x55f5, 0x92ec, 0x18f6, 0x18f6, 0x92f4, 0x55f5, 0x59f6, 0x14f5, 0x92ec, 0x59f6, 0xd7f5, 0x8eeb, 0x38f6, 0x39f6, 0xefeb, 0xd7f5, 0x55ed, 0x96f5, 0xd3f4, 0x76ed, 0x18f6, 0x39f6, 0xd7f5, 0x18f6, 0x6eeb, 0x51ec, 0x14f5, 0x4eeb
};
uint8_t tentativas = 0, recorde = 255;
/* USER CODE END PV */

void SystemClock_Config(void);
static void MX_GPIO_Init(void);
static void MX_SPI1_Init(void);
/* USER CODE BEGIN PFP */
void IniciarJogo();
void SelecionarCarta(char tabuleiro[4][4], uint8_t i, uint8_t j, uint8_t linhas, uint8_t colunas);
void Jogoteste(char tabuleiro[4][4], uint8_t linhas, uint8_t colunas, uint8_t linhaAtual, uint8_t colunaAtual);
void Jogo(char tabuleiro[4][4], uint8_t linhas, uint8_t colunas, uint8_t linhaAtual, uint8_t colunaAtual);
void Jogo2Players(char tabuleiro[4][4], uint8_t linhas, uint8_t colunas, uint8_t linhaAtual, uint8_t colunaAtual);
void GerarParesAleatorios(char tabuleiro[4][4], uint8_t linhas, uint8_t colunas);
bool VerificaSeExisteCartaDisponivelLinha(char tabuleiro[4][4], uint8_t* linhaAtual, uint8_t* colunaAtual, uint8_t colunas);
bool VerificaSeExisteCartaDisponivelColuna(char tabuleiro[4][4],uint8_t* linhaAtual, uint8_t* colunaAtual, uint8_t linhas);
void MoverParaProximaCartaLinha(char tabuleiro[4][4], uint8_t* colunaAtual, uint8_t* linhaAtual, uint8_t colunas, uint8_t sentido);
void MoverParaLinhaComCarta(char tabuleiro[4][4], uint8_t* linhaAtual, uint8_t* colunaAtual, uint8_t linhas, uint8_t colunas, uint8_t sentido);
void MoverParaColunaComCarta(char tabuleiro[4][4], uint8_t* linhaAtual, uint8_t* colunaAtual, uint8_t linhas, uint8_t colunas, uint8_t sentido);
void MoverParaProximaCartaColuna(char tabuleiro[4][4], uint8_t* colunaAtual, uint8_t* linhaAtual, uint8_t linhas, uint8_t sentido);
void AtualizarRecorde(uint8_t atual);
void ExibirFimDeJogo(uint8_t numeroDeTentativasDaRodada, uint8_t recorde);
bool CursorEstaEmCartaSelecionada(uint8_t linha, uint8_t coluna, uint8_t posicoes[2][2], uint8_t totalSelecionadas);
/* USER CODE END PFP */

int main(void)
{

  /* MCU Configuration--------------------------------------------------------*/

  /* Reset of all peripherals, Initializes the Flash interface and the Systick. */
  HAL_Init();

  /* Configure the system clock */
  SystemClock_Config();

  /* Initialize all configured peripherals */
  MX_GPIO_Init();
  MX_SPI1_Init();
  /* USER CODE BEGIN 2 */
  ST7789_Init();

  /* USER CODE END 2 */

  /* Infinite loop */
  /* USER CODE BEGIN WHILE */
  while (1)
  {
	IniciarJogo();
    /* USER CODE END WHILE */

  }
}

void SystemClock_Config(void)
{
  RCC_OscInitTypeDef RCC_OscInitStruct = {0};
  RCC_ClkInitTypeDef RCC_ClkInitStruct = {0};

  /** Initializes the RCC Oscillators according to the specified parameters
  * in the RCC_OscInitTypeDef structure.
  */
  RCC_OscInitStruct.OscillatorType = RCC_OSCILLATORTYPE_HSI;
  RCC_OscInitStruct.HSIState = RCC_HSI_ON;
  RCC_OscInitStruct.HSICalibrationValue = RCC_HSICALIBRATION_DEFAULT;
  RCC_OscInitStruct.PLL.PLLState = RCC_PLL_ON;
  RCC_OscInitStruct.PLL.PLLSource = RCC_PLLSOURCE_HSI_DIV2;
  RCC_OscInitStruct.PLL.PLLMUL = RCC_PLL_MUL16;
  if (HAL_RCC_OscConfig(&RCC_OscInitStruct) != HAL_OK)
  {
    Error_Handler();
  }
  /** Initializes the CPU, AHB and APB buses clocks
  */
  RCC_ClkInitStruct.ClockType = RCC_CLOCKTYPE_HCLK|RCC_CLOCKTYPE_SYSCLK
                              |RCC_CLOCKTYPE_PCLK1|RCC_CLOCKTYPE_PCLK2;
  RCC_ClkInitStruct.SYSCLKSource = RCC_SYSCLKSOURCE_PLLCLK;
  RCC_ClkInitStruct.AHBCLKDivider = RCC_SYSCLK_DIV1;
  RCC_ClkInitStruct.APB1CLKDivider = RCC_HCLK_DIV2;
  RCC_ClkInitStruct.APB2CLKDivider = RCC_HCLK_DIV1;

  if (HAL_RCC_ClockConfig(&RCC_ClkInitStruct, FLASH_LATENCY_2) != HAL_OK)
  {
    Error_Handler();
  }
}

static void MX_SPI1_Init(void)
{

  /* SPI1 parameter configuration*/
  hspi1.Instance = SPI1;
  hspi1.Init.Mode = SPI_MODE_MASTER;
  hspi1.Init.Direction = SPI_DIRECTION_2LINES;
  hspi1.Init.DataSize = SPI_DATASIZE_8BIT;
  hspi1.Init.CLKPolarity = SPI_POLARITY_HIGH;
  hspi1.Init.CLKPhase = SPI_PHASE_1EDGE;
  hspi1.Init.NSS = SPI_NSS_SOFT;
  hspi1.Init.BaudRatePrescaler = SPI_BAUDRATEPRESCALER_8;
  hspi1.Init.FirstBit = SPI_FIRSTBIT_MSB;
  hspi1.Init.TIMode = SPI_TIMODE_DISABLE;
  hspi1.Init.CRCCalculation = SPI_CRCCALCULATION_DISABLE;
  hspi1.Init.CRCPolynomial = 10;
  if (HAL_SPI_Init(&hspi1) != HAL_OK)
  {
    Error_Handler();
  }

}

static void MX_GPIO_Init(void)
{
  GPIO_InitTypeDef GPIO_InitStruct = {0};

  /* GPIO Ports Clock Enable */
  __HAL_RCC_GPIOA_CLK_ENABLE();
  __HAL_RCC_GPIOB_CLK_ENABLE();

  /*Configure GPIO pin Output Level */
  HAL_GPIO_WritePin(ST7789_CS_GPIO_Port, ST7789_CS_Pin, GPIO_PIN_RESET);

  /*Configure GPIO pin Output Level */
  HAL_GPIO_WritePin(GPIOB, ST7789_DC_Pin|ST7789_RST_Pin, GPIO_PIN_RESET);

  /*Configure GPIO pin : ST7789_CS_Pin */
  GPIO_InitStruct.Pin = ST7789_CS_Pin;
  GPIO_InitStruct.Mode = GPIO_MODE_OUTPUT_PP;
  GPIO_InitStruct.Pull = GPIO_NOPULL;
  GPIO_InitStruct.Speed = GPIO_SPEED_FREQ_LOW;
  HAL_GPIO_Init(ST7789_CS_GPIO_Port, &GPIO_InitStruct);

  /*Configure GPIO pins : ST7789_DC_Pin ST7789_RST_Pin */
  GPIO_InitStruct.Pin = ST7789_DC_Pin|ST7789_RST_Pin;
  GPIO_InitStruct.Mode = GPIO_MODE_OUTPUT_PP;
  GPIO_InitStruct.Pull = GPIO_NOPULL;
  GPIO_InitStruct.Speed = GPIO_SPEED_FREQ_LOW;
  HAL_GPIO_Init(GPIOB, &GPIO_InitStruct);

  /*Configure GPIO pins : PA9 PA10 PA11 PA12 */
  GPIO_InitStruct.Pin = GPIO_PIN_9|GPIO_PIN_10|GPIO_PIN_11|GPIO_PIN_12;
  GPIO_InitStruct.Mode = GPIO_MODE_INPUT;
  GPIO_InitStruct.Pull = GPIO_PULLUP;
  HAL_GPIO_Init(GPIOA, &GPIO_InitStruct);

}

/* USER CODE BEGIN 4 */
uint8_t linhas = 4, colunas = 4, jogadores = 1;
uint16_t seta = WHITE;
uint32_t last_tick = 0;
bool menu = true;
int x=5, y=79,z=30,p=42,P=42;
uint8_t opcao=0,tela=0;

void setar() {

		if(HAL_GPIO_ReadPin(GPIOA, GPIO_PIN_11) == 0 && tela!=2){
			ST7789_DrawFilledTriangle(x+18, y-6, x+20, y+6, x+30, y, BLACK);
			ST7789_DrawFilledRectangle(x, y-3, 25 , 6, BLACK);
			if(tela==0){
			switch(opcao){
					case 0:
					ST7789_Fill_Color(BLACK);
					menu=false;
					break;
					case 1:
					ST7789_Fill_Color(BLACK);
					if(p==152) x+=115;
					opcao=0;
					z=80;
					tela=1;
					break;
					case 2:
				    ST7789_Fill_Color(BLACK);
					tela=2;
					opcao=0;
				   break;
			 }
			} else{if(opcao==0&&linhas==4){
		        ST7789_WriteChar(p, 98 , 'x', Font_16x26, BLACK, BLACK);
				x+=115;
				p=152;
				linhas=3;
				HAL_Delay(100);
			} else if(opcao==0&&linhas==3){
		        ST7789_WriteChar(p, 98 , 'x', Font_16x26, BLACK, BLACK);
				x-=115;
				p=42;
				linhas=4;
				HAL_Delay(100);
			} else if(opcao==1&&jogadores==1){
		        ST7789_WriteChar(P, 178 , 'x', Font_16x26, BLACK, BLACK);
				x+=115;
			    P=152;
			    jogadores=2;
			    HAL_Delay(100);
			}else if(opcao==1&&jogadores==2){
				ST7789_WriteChar(P, 178 , 'x', Font_16x26, BLACK, BLACK);
				x-=115;
			    P=42;
			    jogadores=1;
			    HAL_Delay(100);
			}
			}
			}
		else if(((HAL_GPIO_ReadPin(GPIOA, GPIO_PIN_12) == 0)&& opcao>0)&&tela!=2){
					if(p==42 &&tela==1){
						ST7789_DrawFilledTriangle(x+18, y-6, x+20, y+6, x+30, y, BLACK);
						ST7789_DrawFilledRectangle(x, y-3, 25 , 6, BLACK);
						x=5;
					}
					else if(p!=42&&tela==1) {
						ST7789_DrawFilledTriangle(x+18, y-6, x+20, y+6, x+30, y, BLACK);
						ST7789_DrawFilledRectangle(x, y-3, 25 , 6, BLACK);
						x=120;
					} else{
						 ST7789_DrawFilledTriangle(x+18, y-6, x+20, y+6, x+30, y, BLACK);
						 ST7789_DrawFilledRectangle(x, y-3, 25 , 6, BLACK);
					}

		    	    last_tick=HAL_GetTick();

					y-=z;
		    		opcao--;
		    		HAL_Delay(100);
		    	}
			else if(((HAL_GPIO_ReadPin(GPIOA, GPIO_PIN_10) == 0)&& opcao<2&&tela==0||(HAL_GPIO_ReadPin(GPIOA, GPIO_PIN_10) == 0)&&tela==1&&opcao<1)&&tela!=2){
				 	if(P==42 &&tela==1){
				 		ST7789_DrawFilledTriangle(x+18, y-6, x+20, y+6, x+30, y, BLACK);
				 		ST7789_DrawFilledRectangle(x, y-3, 25 , 6, BLACK);
				 		x=5;
				 	}
				 	else if(P!=42&&tela==1){
				 		ST7789_DrawFilledTriangle(x+18, y-6, x+20, y+6, x+30, y, BLACK);
				 		ST7789_DrawFilledRectangle(x, y-3, 25 , 6, BLACK);
				 		x=120;
				 	}else{
				 		ST7789_DrawFilledTriangle(x+18, y-6, x+20, y+6, x+30, y, BLACK);
				 		ST7789_DrawFilledRectangle(x, y-3, 25 , 6, BLACK);
				 	}
				    last_tick=HAL_GetTick();
				    ST7789_DrawFilledTriangle(x+18, y-6, x+20, y+6, x+30, y, BLACK);
				    ST7789_DrawFilledRectangle(x, y-3, 25 , 6, BLACK);
					y+=z;
					opcao++;
					HAL_Delay(100);
			}
			else if(HAL_GPIO_ReadPin(GPIOA, GPIO_PIN_9) == 0&&tela>0){

			    ST7789_Fill_Color(BLACK);
			    opcao=0;
			    x=5;
			    y=79;
			    z=30;
			    tela=0;
			}
			if(tela!=2){
		if ((HAL_GetTick()-last_tick)>500){
			if(seta==WHITE)
				{
					seta=BLACK;
				}
			else if(seta==BLACK)
				{
				seta=WHITE;
				}
			last_tick=HAL_GetTick();
		}
		ST7789_DrawFilledTriangle(x+18, y-6, x+20, y+6, x+30, y, seta);
		ST7789_DrawFilledRectangle(x, y-3, 25 , 6, seta);
	} else{
		seta=BLACK;
		ST7789_DrawFilledTriangle(x+18, y-6, x+20, y+6, x+30, y, seta);
		ST7789_DrawFilledRectangle(x, y-3, 25 , 6, seta);
	}
	}

void NavegadorCursor(char tabuleiro[4][4], uint8_t* linhaAtual, uint8_t* colunaAtual, uint8_t linhas, uint8_t colunas){
		if (!HAL_GPIO_ReadPin(GPIOA, GPIO_PIN_9)) { //esquerda
			if(VerificaSeExisteCartaDisponivelLinha(tabuleiro, linhaAtual, colunaAtual, colunas)){
				MoverParaProximaCartaLinha(tabuleiro, colunaAtual, linhaAtual, colunas, 0);
				HAL_Delay(150);
			}
            else{
            	MoverParaLinhaComCarta(tabuleiro, linhaAtual, colunaAtual, linhas, colunas, 0);
            	HAL_Delay(150);
            }
        }

		else if (!HAL_GPIO_ReadPin(GPIOA, GPIO_PIN_10)) { // baixo
			if(VerificaSeExisteCartaDisponivelColuna(tabuleiro, linhaAtual, colunaAtual, linhas)){
				MoverParaProximaCartaColuna(tabuleiro, colunaAtual, linhaAtual, linhas, 1);
				HAL_Delay(150);
			}
			else{
				MoverParaColunaComCarta(tabuleiro, linhaAtual, colunaAtual, linhas, colunas, 1);
				HAL_Delay(150);
			}

        }

		else if (!HAL_GPIO_ReadPin(GPIOA, GPIO_PIN_11)) { //direita
			if(VerificaSeExisteCartaDisponivelLinha(tabuleiro, linhaAtual, colunaAtual, colunas)){
				MoverParaProximaCartaLinha(tabuleiro, colunaAtual, linhaAtual, colunas, 1);
				HAL_Delay(150);
			}
			else{
			    MoverParaLinhaComCarta(tabuleiro, linhaAtual, colunaAtual, linhas, colunas, 1);
			    HAL_Delay(150);
			}
		}

		/*else if (!HAL_GPIO_ReadPin(GPIOA, GPIO_PIN_12)) { //cima
			if(VerificaSeExisteCartaDisponivelColuna(tabuleiro, linhaAtual, colunaAtual, linhas)){
				MoverParaProximaCartaColuna(tabuleiro, colunaAtual, linhaAtual, linhas, 0);
				HAL_Delay(150);
			}
			else{
				MoverParaColunaComCarta(tabuleiro, linhaAtual, colunaAtual, linhas, colunas, 0);
				HAL_Delay(150);
			}
		}*/
}

bool VerificaSeExisteCartaDisponivelLinha(char tabuleiro[4][4], uint8_t* linhaAtual, uint8_t* colunaAtual, uint8_t colunas){
	for(int c = 0; c < colunas; c++){
		if(tabuleiro[*linhaAtual][c] != '0' && c != *colunaAtual) return true;
	}
	return false;
}

void MoverParaProximaCartaLinha(char tabuleiro[4][4], uint8_t* colunaAtual, uint8_t* linhaAtual, uint8_t colunas, uint8_t sentido){ // 1 pra direita ou 0 pra esquerda
	uint8_t original = *colunaAtual;
	do{
		if(sentido>0) *colunaAtual = (*colunaAtual + 1) % colunas;
		else *colunaAtual = (*colunaAtual == 0) ? colunas - 1 : *colunaAtual - 1;
	} while(tabuleiro[*linhaAtual][*colunaAtual] == '0' && *colunaAtual != original);
	HAL_Delay(150);
}

void MoverParaLinhaComCarta(char tabuleiro[4][4], uint8_t* linhaAtual, uint8_t* colunaAtual, uint8_t linhas, uint8_t colunas, uint8_t sentido) { // 1 para baixo ou 0 para cima
	uint8_t linhaOriginal = *linhaAtual;
	do {
		if(sentido > 0)*linhaAtual = (*linhaAtual + 1) % linhas;
		else *linhaAtual = (*linhaAtual == 0) ? linhas - 1 : *linhaAtual - 1;
	} while (!VerificaSeExisteCartaDisponivelLinha(tabuleiro, linhaAtual, colunaAtual, colunas) && *linhaAtual != linhaOriginal);
	for (int c = 0; c < colunas; c++) {
		if (tabuleiro[*linhaAtual][c] != '0') {
			*colunaAtual = c;
			break;
		}
	}
	HAL_Delay(150);
}

void MoverParaProximaCartaColuna(char tabuleiro[4][4], uint8_t* colunaAtual, uint8_t* linhaAtual, uint8_t linhas, uint8_t sentido){
	uint8_t original = *linhaAtual;
	do{
		if(sentido > 0) *linhaAtual = (*linhaAtual + 1) % linhas;
		else  *linhaAtual = (*linhaAtual == 0) ? linhas - 1 : *linhaAtual - 1;
	} while(tabuleiro[*linhaAtual][*colunaAtual] == '0' && *linhaAtual != original);
	HAL_Delay(150);
}

void MoverParaColunaComCarta(char tabuleiro[4][4], uint8_t* linhaAtual, uint8_t* colunaAtual, uint8_t linhas, uint8_t colunas, uint8_t sentido){
	uint8_t original = *colunaAtual;
	do {
		if(sentido > 0) *colunaAtual = (*colunaAtual + 1) % colunas;
		else *colunaAtual = (*colunaAtual == 0) ? colunas - 1 : *colunaAtual - 1;
	} while (!VerificaSeExisteCartaDisponivelColuna(tabuleiro, linhaAtual, colunaAtual, linhas) && *colunaAtual != original);
	for (int l = 0; l < linhas; l++) {
			if (tabuleiro[l][*colunaAtual] != '0') {
				*linhaAtual = l;
				break;
			}
		}
	HAL_Delay(150);
}

bool VerificaSeExisteCartaDisponivelColuna(char tabuleiro[4][4], uint8_t* linhaAtual, uint8_t* colunaAtual, uint8_t linhas){
	for(int l = 0; l<linhas; l++){
		if(tabuleiro[l][*colunaAtual] != '0' && l != *linhaAtual) return true;
	}
	return false;
}

void IniciarJogo () {
	ST7789_Fill_Color(BLACK);

	menu = true;
	while(menu){
		ST7789_WriteString(0,0, "Matching Pairs", Font_16x26, WHITE, BLACK);
		ST7789_WriteString(88,30, "Game", Font_16x26, WHITE, BLACK);
	    ST7789_DrawFilledRectangle(5, 43, 70, 6, WHITE);
	    ST7789_DrawFilledRectangle(165, 43, 70 , 6, WHITE);
	    if (tela==0){
	    	ST7789_WriteString(40,70, "Iniciar jogo", Font_11x18, WHITE, BLACK);
	    	ST7789_WriteString(40,100, "Configuracoes", Font_11x18, WHITE, BLACK);
	    	ST7789_WriteString(40,130, "Recordes", Font_11x18, WHITE, BLACK);

	    }
	    else if(tela==1){
	    	ST7789_WriteString(0,70, "Tamanho do tabuleiro", Font_11x18, WHITE, BLACK);
	    	ST7789_DrawRectangle(40, 100, 60, 120, WHITE);
	    	ST7789_DrawRectangle(150, 100, 170,120, WHITE);
	        ST7789_WriteChar(p, 98 , 'x', Font_16x26, WHITE, BLACK);
	        ST7789_WriteChar(P, 178 , 'x', Font_16x26, WHITE, BLACK);
	    	ST7789_WriteString(65,101, "4x4", Font_11x18, WHITE, BLACK);
	    	ST7789_WriteString(175,101, "3x4", Font_11x18, WHITE, BLACK);
	    	ST7789_WriteString(0,150, "Quantidade de players", Font_11x18, WHITE, BLACK);
	    	ST7789_DrawRectangle(40, 180, 60, 200, WHITE);
	    	ST7789_DrawRectangle(150,180, 170,200, WHITE);
	    	ST7789_WriteString(65,181, "1", Font_11x18, WHITE, BLACK);
	    	ST7789_WriteString(175,181, "2", Font_11x18, WHITE, BLACK);
	     }
		 else if(tela==2){
			ST7789_WriteString(60,80, "Recordes", Font_16x26, WHITE, BLACK);
            if(recorde==255){
				ST7789_WriteString(40,140, "Nenhum recorde", Font_11x18, WHITE, BLACK);
		    } else{
			char records[3];
			sprintf(records, "%d", recorde);
			ST7789_WriteString(40,140, "seu recorde foi", Font_11x18, WHITE, BLACK);
			ST7789_WriteString(110,160, records, Font_11x18, WHITE, BLACK);
		 	}
		}
	     setar();
	 }

     char tabuleiro[linhas][colunas];
     tentativas = 0;
     GerarParesAleatorios(tabuleiro, linhas, colunas);
     if(jogadores == 1){
    	 Jogo(tabuleiro, linhas, colunas, 0, 0);
    	 AtualizarRecorde(tentativas);
    	 ExibirFimDeJogo(tentativas, recorde);
     }
     else Jogo2Players(tabuleiro, linhas, colunas, 0, 0);
}

void GerarParesAleatorios(char tabuleiro[4][4], uint8_t linhas, uint8_t colunas){
	char temp[linhas*colunas];
	for(int i = 0; i< linhas*colunas/2; i++){
		temp[i*2] = 'a' + i;
		temp[i*2 + 1] = 'a' + i;
	}
	for(int i = linhas*colunas - 1; i>0; i--){
		uint8_t j = rand() % (i+1);
		char tmp = temp[i];
		temp[i] = temp[j];
		temp[j] = tmp;
	}
	uint8_t count = 0;
	for(int i = 0; i<linhas; i++){
		for(int j = 0; j<colunas; j++){
			tabuleiro[i][j] = temp[count];
			count++;
		}
	}
}

void SelecionarCarta(char tabuleiro[4][4], uint8_t i, uint8_t j, uint8_t linhas, uint8_t colunas){
	uint8_t x = 240/colunas * j, y = 240/linhas * i;
	switch(tabuleiro[i][j]){
	case 'a':
		DrawCard(x, y, RED, (const uint64_t*) hearts, WHITE);
		break;
	case 'b':
		DrawCard(x, y, RED, (const uint64_t*) diamonds, WHITE);
		break;
	case 'c':
		DrawCard(x, y, BLACK, (const uint64_t*) clubs, WHITE);
		break;
	case 'd':
		DrawCard(x, y, BLACK, (const uint64_t*) spades, WHITE);
		break;
	case 'e':
		DrawCard(x, y, BLACK, (const uint64_t*) hearts, WHITE);
		break;
	case 'f':
		DrawCard(x, y, BLACK, (const uint64_t*) diamonds, WHITE);
		break;
	case 'g':
		DrawCard(x, y, RED, (const uint64_t*) clubs, WHITE);
		break;
	case 'h':
		DrawCard(x, y, RED, (const uint64_t*) spades, WHITE);
		break;
	}
}

void VirarTodasCartas(uint8_t linhas, uint8_t colunas){
	uint8_t x = 240/colunas, y = 240/linhas;
	for(int i = 0; i<linhas; i++){
		for(int j = 0; j<colunas; j++){
			ST7789_DrawImage(x*j, y*i, 50, 50, (const uint16_t *)fundocarta);
		}
	}
}

void AtualizarRecorde(uint8_t atual){
	recorde = (recorde > atual) ? atual : recorde;
}

bool CompararPares(char a, char b){
	return a==b;
}

void AtualizarTentativas(uint8_t *tentativas){
	(*tentativas)++;
}

bool VerificaFimDeJogo(uint8_t acertos, uint8_t linhas, uint8_t colunas){
	if(acertos >= linhas*colunas/2) return true;
	return false;
}

void ExibirFimDeJogo(uint8_t numeroDeTentativasDaRodada, uint8_t recorde){
	ST7789_Fill_Color(BLACK);
	ST7789_WriteString(50, 150, "Parabens!", Font_16x26, WHITE, BLACK);
	DrawCard(100, 60, RED, (const uint64_t*) hearts, BLACK);
	HAL_Delay(200);
	DrawCard(100, 60, WHITE, (const uint64_t*) hearts, BLACK);
	HAL_Delay(200);
	DrawCard(100, 60, BLUE, (const uint64_t*) hearts, BLACK);
	HAL_Delay(200);
	ST7789_Fill_Color(BLACK);
	ST7789_WriteString(20, 20, "Fim de Jogo!", Font_11x18, WHITE, BLACK);
	ST7789_WriteString(20, 50, "Tentativas:", Font_11x18, WHITE, BLACK);
	ST7789_WriteString(20, 80, "Recorde:", Font_11x18, WHITE, BLACK);
	ST7789_WriteString(20, 120, "Aperte qualquer", Font_11x18, WHITE, BLACK);
	ST7789_WriteString(80, 138, "botao", Font_11x18, WHITE, BLACK);
	ST7789_WriteString(30, 156, "para reiniciar", Font_11x18, WHITE, BLACK);

	char tentativasStr[3], recordeStr[3];
	sprintf(tentativasStr, "%d", numeroDeTentativasDaRodada);
	sprintf(recordeStr, "%d", recorde);
	ST7789_WriteString(150, 50, tentativasStr, Font_11x18, WHITE, BLACK);
	ST7789_WriteString(110, 80, recordeStr, Font_11x18, WHITE, BLACK);

	while(HAL_GPIO_ReadPin(GPIOA, GPIO_PIN_9) && HAL_GPIO_ReadPin(GPIOA, GPIO_PIN_10) && HAL_GPIO_ReadPin(GPIOA, GPIO_PIN_11) && HAL_GPIO_ReadPin(GPIOA, GPIO_PIN_12));
	ST7789_Fill_Color(BLACK);
}

void FimDeJogoDoisJogadores(uint8_t scorePlayer1, uint8_t scorePlayer2){
	ST7789_Fill_Color(BLACK);
	ST7789_WriteString(20, 20, "Fim de Jogo!", Font_11x18, WHITE, BLACK);
	if(scorePlayer1 == scorePlayer2) ST7789_WriteString(20, 80, "Empate", Font_11x18, WHITE, BLACK);
	ST7789_WriteString(20, 50, "Parabens!", Font_11x18, WHITE, BLACK);
	if(scorePlayer1 != scorePlayer2) ST7789_WriteString(20, 80, (scorePlayer1>scorePlayer2) ? "Vitoria Player1" : "Vitoria Player2", Font_11x18, (scorePlayer1>scorePlayer2) ? BLUE : YELLOW, BLACK);

	ST7789_WriteString(20, 120, "Aperte qualquer", Font_11x18, WHITE, BLACK);
	ST7789_WriteString(80, 138, "botao", Font_11x18, WHITE, BLACK);
	ST7789_WriteString(30, 156, "para reiniciar", Font_11x18, WHITE, BLACK);

	while(HAL_GPIO_ReadPin(GPIOA, GPIO_PIN_9) && HAL_GPIO_ReadPin(GPIOA, GPIO_PIN_10) && HAL_GPIO_ReadPin(GPIOA, GPIO_PIN_11) && HAL_GPIO_ReadPin(GPIOA, GPIO_PIN_12));
	ST7789_Fill_Color(BLACK);
}

void Jogo(char tabuleiro[4][4], uint8_t linhas, uint8_t colunas, uint8_t linhaAtual, uint8_t colunaAtual){
	ST7789_Fill_Color(BLACK);
	uint8_t totalDeCartasSelecionadas = 0, acertos = 0, posicoesCartasSelecionadas[2][2];
	for(int i = 0; i < linhas; i++){
		for(int j = 0; j < colunas; j++){
			SelecionarCarta(tabuleiro, i, j, linhas, colunas);
		}
	}
	HAL_Delay(1500);
	VirarTodasCartas(linhas, colunas);
	uint8_t ultimaPosicao[2] = {100, 100}, ultimaPosicaoCursor[2] = {100,100};
	while(!VerificaFimDeJogo(acertos, linhas, colunas)){
		NavegadorCursor(tabuleiro, &linhaAtual, &colunaAtual, linhas, colunas);
		if (!CursorEstaEmCartaSelecionada(linhaAtual, colunaAtual, posicoesCartasSelecionadas, totalDeCartasSelecionadas) && (ultimaPosicaoCursor[0] != linhaAtual || ultimaPosicaoCursor[1] != colunaAtual)) {
			if (ultimaPosicaoCursor[0] < linhas && ultimaPosicaoCursor[1] < colunas && tabuleiro[ultimaPosicaoCursor[0]][ultimaPosicaoCursor[1]] != '0' && !CursorEstaEmCartaSelecionada(ultimaPosicaoCursor[0], ultimaPosicaoCursor[1], posicoesCartasSelecionadas, totalDeCartasSelecionadas)) {
				ST7789_DrawImage(240 / colunas * ultimaPosicaoCursor[1], 240 / linhas * ultimaPosicaoCursor[0], 50, 50, (const uint16_t *)fundocarta);
			}
			ST7789_DrawFilledCircle(240/colunas * colunaAtual + 25, 240/linhas * linhaAtual + 25, 20, BLUE);
			ultimaPosicaoCursor[0] = linhaAtual;
			ultimaPosicaoCursor[1] = colunaAtual;
		}
		if(!HAL_GPIO_ReadPin(GPIOA, GPIO_PIN_12) && (linhaAtual != ultimaPosicao[0] || colunaAtual != ultimaPosicao[1])){
			SelecionarCarta(tabuleiro, linhaAtual, colunaAtual, linhas, colunas);
			posicoesCartasSelecionadas[totalDeCartasSelecionadas%2][0] = linhaAtual;
			posicoesCartasSelecionadas[totalDeCartasSelecionadas%2][1] = colunaAtual;
			totalDeCartasSelecionadas++;
			ultimaPosicao[0] = linhaAtual;
			ultimaPosicao[1] = colunaAtual;
			if(totalDeCartasSelecionadas % 2 == 0){
				AtualizarTentativas(&tentativas);
				char carta1 = tabuleiro[posicoesCartasSelecionadas[0][0]][posicoesCartasSelecionadas[0][1]];
				char carta2 = tabuleiro[posicoesCartasSelecionadas[1][0]][posicoesCartasSelecionadas[1][1]];
				if(CompararPares(carta1, carta2)){
					acertos++;
					tabuleiro[posicoesCartasSelecionadas[0][0]][posicoesCartasSelecionadas[0][1]] = '0';
					tabuleiro[posicoesCartasSelecionadas[1][0]][posicoesCartasSelecionadas[1][1]] = '0';
				}
				else{
					HAL_Delay(1000);
					ST7789_DrawImage(240/colunas*posicoesCartasSelecionadas[0][1], 240/linhas*posicoesCartasSelecionadas[0][0], 50, 50, (const uint16_t *)fundocarta);
					ST7789_DrawImage(240/colunas*posicoesCartasSelecionadas[1][1], 240/linhas*posicoesCartasSelecionadas[1][0], 50, 50, (const uint16_t *)fundocarta);
					ultimaPosicao[0] = 100;
					ultimaPosicao[1] = 100;
				}
			}
		}
	}
}

void Jogo2Players(char tabuleiro[4][4], uint8_t linhas, uint8_t colunas, uint8_t linhaAtual, uint8_t colunaAtual){
	ST7789_Fill_Color(BLACK);
	uint8_t totalDeCartasSelecionadas = 0, acertosJogador1 = 0, acertosJogador2 = 0, posicoesCartasSelecionadas[2][2], jogadorAtual = 0;
	for(int i = 0; i < linhas; i++){
		for(int j = 0; j < colunas; j++){
			SelecionarCarta(tabuleiro, i, j, linhas, colunas);
		}
	}
	HAL_Delay(1500);
	VirarTodasCartas(linhas, colunas);
	uint8_t ultimaPosicao[2] = {100, 100}, ultimaPosicaoCursor[2] = {100,100};
	while(!VerificaFimDeJogo(acertosJogador1 + acertosJogador2, linhas, colunas)){
		NavegadorCursor(tabuleiro, &linhaAtual, &colunaAtual, linhas, colunas);
		if (!CursorEstaEmCartaSelecionada(linhaAtual, colunaAtual, posicoesCartasSelecionadas, totalDeCartasSelecionadas) && (ultimaPosicaoCursor[0] != linhaAtual || ultimaPosicaoCursor[1] != colunaAtual)) {
			if (ultimaPosicaoCursor[0] < linhas && ultimaPosicaoCursor[1] < colunas && tabuleiro[ultimaPosicaoCursor[0]][ultimaPosicaoCursor[1]] != '0' && !CursorEstaEmCartaSelecionada(ultimaPosicaoCursor[0], ultimaPosicaoCursor[1], posicoesCartasSelecionadas, totalDeCartasSelecionadas)) {
				ST7789_DrawImage(240 / colunas * ultimaPosicaoCursor[1], 240 / linhas * ultimaPosicaoCursor[0], 50, 50, (const uint16_t *)fundocarta);
			}
			ST7789_DrawFilledCircle(240/colunas * colunaAtual + 25, 240/linhas * linhaAtual + 25, 20, (jogadorAtual%2 == 0) ? BLUE : YELLOW);
			ultimaPosicaoCursor[0] = linhaAtual;
			ultimaPosicaoCursor[1] = colunaAtual;
		}
		if(!HAL_GPIO_ReadPin(GPIOA, GPIO_PIN_12) && (linhaAtual != ultimaPosicao[0] || colunaAtual != ultimaPosicao[1])){
			SelecionarCarta(tabuleiro, linhaAtual, colunaAtual, linhas, colunas);
			posicoesCartasSelecionadas[totalDeCartasSelecionadas%2][0] = linhaAtual;
			posicoesCartasSelecionadas[totalDeCartasSelecionadas%2][1] = colunaAtual;
			totalDeCartasSelecionadas++;
			ultimaPosicao[0] = linhaAtual;
			ultimaPosicao[1] = colunaAtual;
			if(totalDeCartasSelecionadas % 2 == 0){
				AtualizarTentativas(&tentativas);
				char carta1 = tabuleiro[posicoesCartasSelecionadas[0][0]][posicoesCartasSelecionadas[0][1]];
				char carta2 = tabuleiro[posicoesCartasSelecionadas[1][0]][posicoesCartasSelecionadas[1][1]];
				if(CompararPares(carta1, carta2)){
					if(jogadorAtual == 0) acertosJogador1++;
					else acertosJogador2++;
					tabuleiro[posicoesCartasSelecionadas[0][0]][posicoesCartasSelecionadas[0][1]] = '0';
					tabuleiro[posicoesCartasSelecionadas[1][0]][posicoesCartasSelecionadas[1][1]] = '0';
				}
				else{
					HAL_Delay(1000);
					ST7789_DrawImage(240/colunas*posicoesCartasSelecionadas[0][1], 240/linhas*posicoesCartasSelecionadas[0][0], 50, 50, (const uint16_t *)fundocarta);
					ST7789_DrawImage(240/colunas*posicoesCartasSelecionadas[1][1], 240/linhas*posicoesCartasSelecionadas[1][0], 50, 50, (const uint16_t *)fundocarta);
					ultimaPosicao[0] = 100;
					ultimaPosicao[1] = 100;
				}
				jogadorAtual = (jogadorAtual+1)%2;
			}
		}
	}
	FimDeJogoDoisJogadores(acertosJogador1, acertosJogador2);
}

bool CursorEstaEmCartaSelecionada(uint8_t linha, uint8_t coluna, uint8_t posicoes[2][2], uint8_t totalSelecionadas) {
	if (totalSelecionadas == 0) return false;

	for (int i = 0; i < 2; i++) {
		if (linha == posicoes[i][0] && coluna == posicoes[i][1]) {
			return true;
		}
	}
	return false;
}

/* USER CODE END 4 */

void Error_Handler(void)
{
  __disable_irq();
  while (1)
  {
  }
}

/************************ (C) COPYRIGHT STMicroelectronics *****END OF FILE****/
